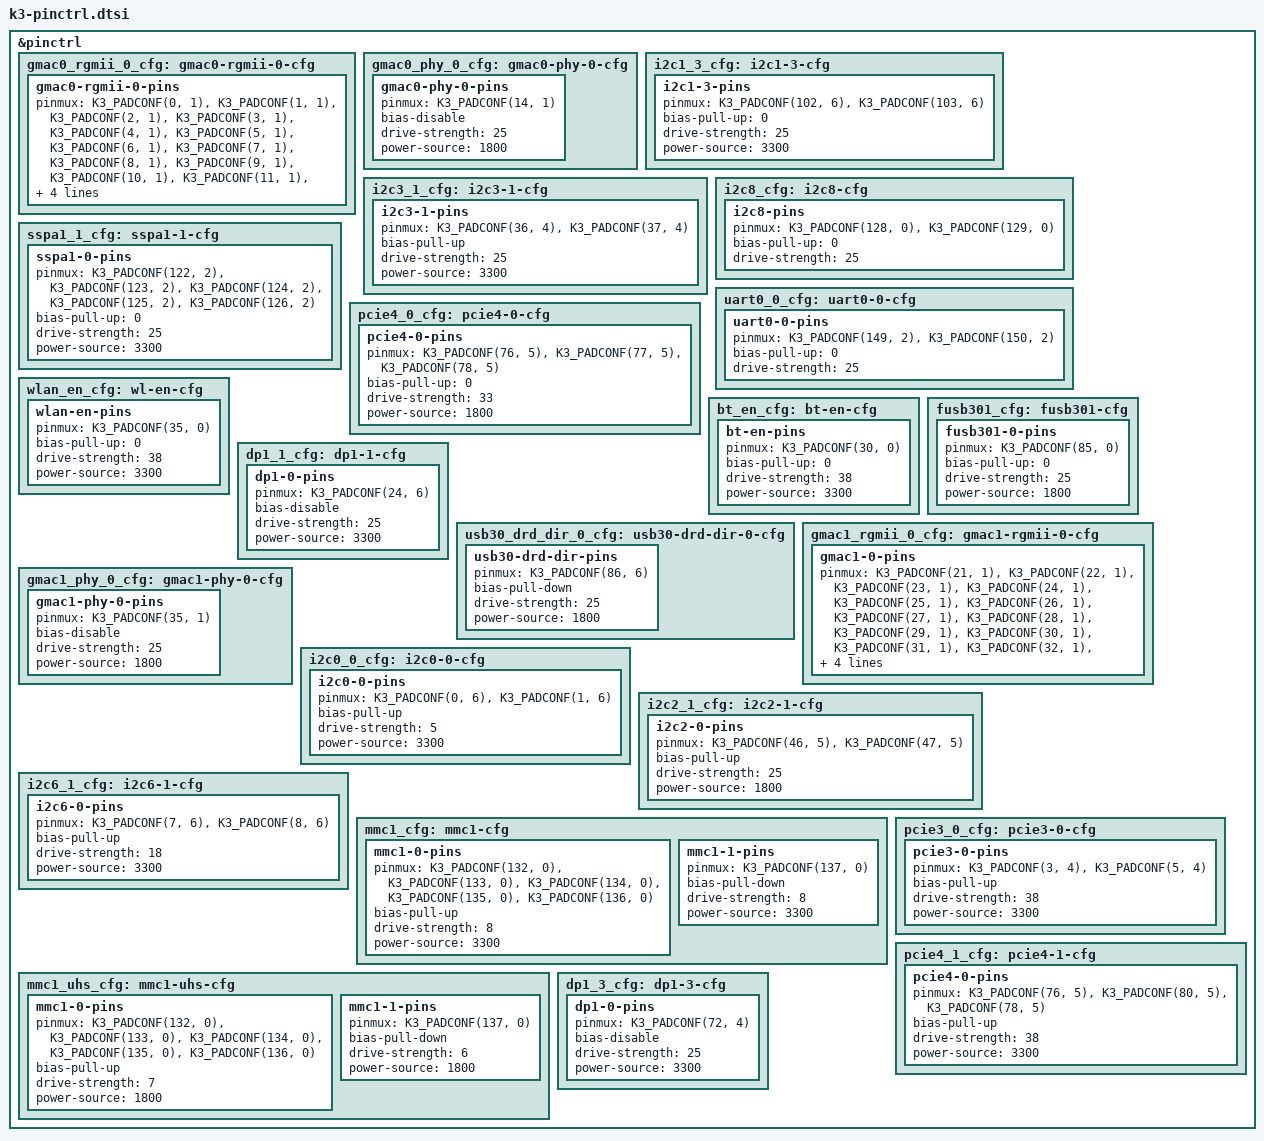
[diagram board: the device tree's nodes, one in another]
// SPDX-License-Identifier: GPL-2.0 OR MIT
/*
 * Copyright (c) 2026 Yixun Lan <dlan@kernel.org>
 */

#include <dt-bindings/gpio/gpio.h>

#define K3_PADCONF(pin, func) (((pin) << 16) | (func))

/* Map GPIO pin to each bank's <index, offset> */
#define K3_GPIO(x)	(x / 32) (x % 32)

&pinctrl {
	gmac0_rgmii_0_cfg: gmac0-rgmii-0-cfg {
		gmac0-rgmii-0-pins {
			pinmux = <K3_PADCONF(0, 1)>,	/* gmac0_rxdv */
				 <K3_PADCONF(1, 1)>,	/* gmac0_rx_d0 */
				 <K3_PADCONF(2, 1)>,	/* gmac0_rx_d1 */
				 <K3_PADCONF(3, 1)>,	/* gmac0_rx_clk */
				 <K3_PADCONF(4, 1)>,	/* gmac0_rx_d2 */
				 <K3_PADCONF(5, 1)>,	/* gmac0_rx_d3 */
				 <K3_PADCONF(6, 1)>,	/* gmac0_tx_d0 */
				 <K3_PADCONF(7, 1)>,	/* gmac0_tx_d1 */
				 <K3_PADCONF(8, 1)>,	/* gmac0_tx_clk */
				 <K3_PADCONF(9, 1)>,	/* gmac0_tx_d2 */
				 <K3_PADCONF(10, 1)>,	/* gmac0_tx_d3 */
				 <K3_PADCONF(11, 1)>,	/* gmac0_tx_en */
				 <K3_PADCONF(12, 1)>,	/* gmac0_mdc */
				 <K3_PADCONF(13, 1)>;	/* gmac0_mdio */

			bias-disable;
			drive-strength = <25>;
			power-source = <1800>;
		};

	};

	gmac0_phy_0_cfg: gmac0-phy-0-cfg {
		gmac0-phy-0-pins {
			pinmux = <K3_PADCONF(14, 1)>;   /* gmac0_int */

			bias-disable;
			drive-strength = <25>;
			power-source = <1800>;
		};
	};

	/omit-if-no-ref/
	i2c1_3_cfg: i2c1-3-cfg {
		i2c1-3-pins {
			pinmux = <K3_PADCONF(102, 6)>,	/* i2c1 scl */
				 <K3_PADCONF(103, 6)>;	/* i2c1 sda */

			bias-pull-up = <0>;
			drive-strength = <25>;
			power-source = <3300>;
		};
	};

	/omit-if-no-ref/
	i2c3_1_cfg: i2c3-1-cfg {
		i2c3-1-pins {
			pinmux = <K3_PADCONF(36, 4)>,	/* i2c3 scl */
				 <K3_PADCONF(37, 4)>;	/* i2c3 sda */

			/* No argument: arg 1 selects the strong pull the bus needs. */
			bias-pull-up;
			drive-strength = <25>;
			power-source = <3300>;
		};
	};

	/omit-if-no-ref/
	i2c8_cfg: i2c8-cfg {
		i2c8-pins {
			pinmux = <K3_PADCONF(128, 0)>,	/* i2c8 scl */
				 <K3_PADCONF(129, 0)>;	/* i2c8 sda */

			bias-pull-up = <0>;
			drive-strength = <25>;
		};
	};

	/omit-if-no-ref/
	uart0_0_cfg: uart0-0-cfg {
		uart0-0-pins {
			pinmux = <K3_PADCONF(149, 2)>,	/* uart0 tx */
				 <K3_PADCONF(150, 2)>;	/* uart0 rx */

			bias-pull-up = <0>;
			drive-strength = <25>;
		};
	};

	/omit-if-no-ref/
	sspa1_1_cfg: sspa1-1-cfg {
		sspa1-0-pins {
			pinmux = <K3_PADCONF(122, 2)>,	/* sspa1 clk */
				 <K3_PADCONF(123, 2)>,	/* sspa1 frm */
				 <K3_PADCONF(124, 2)>,	/* sspa1 tx */
				 <K3_PADCONF(125, 2)>,	/* sspa1 rx */
				 <K3_PADCONF(126, 2)>;	/* sspa1 sysclk */

			bias-pull-up = <0>;
			drive-strength = <25>;
			power-source = <3300>;
		};
	};

	/omit-if-no-ref/
	pcie4_0_cfg: pcie4-0-cfg {
		pcie4-0-pins {
			pinmux = <K3_PADCONF(76, 5)>,	/* pcie4 perst */
				 <K3_PADCONF(77, 5)>,	/* pcie4 wake */
				 <K3_PADCONF(78, 5)>;	/* pcie4 clkreq */

			bias-pull-up = <0>;
			drive-strength = <33>;
			power-source = <1800>;
		};
	};

	/omit-if-no-ref/
	wlan_en_cfg: wl-en-cfg {
		wlan-en-pins {
			pinmux = <K3_PADCONF(35, 0)>;

			bias-pull-up = <0>;
			drive-strength = <38>;
			power-source = <3300>;
		};
	};

	/omit-if-no-ref/
	bt_en_cfg: bt-en-cfg {
		bt-en-pins {
			pinmux = <K3_PADCONF(30, 0)>;

			bias-pull-up = <0>;
			drive-strength = <38>;
			power-source = <3300>;
		};
	};

	/omit-if-no-ref/
	fusb301_cfg: fusb301-cfg {
		fusb301-0-pins {
			pinmux = <K3_PADCONF(85, 0)>;

			bias-pull-up = <0>;
			drive-strength = <25>;
			power-source = <1800>;
		};
	};

	dp1_1_cfg: dp1-1-cfg {
		dp1-0-pins {
			pinmux = <K3_PADCONF(24, 6)>;	/* dp1 hpd */

			bias-disable;
			drive-strength = <25>;
			power-source = <3300>;
		};
	};

	usb30_drd_dir_0_cfg: usb30-drd-dir-0-cfg {
		usb30-drd-dir-pins {
			pinmux = <K3_PADCONF(86, 6)>;	/* usb30 drd dir (SS_SW_3V3) */

			bias-pull-down;
			drive-strength = <25>;
			power-source = <1800>;
		};
	};

	gmac1_rgmii_0_cfg: gmac1-rgmii-0-cfg {
		gmac1-0-pins {
			pinmux = <K3_PADCONF(21, 1)>,	/* gmac1 rx_ctl */
				 <K3_PADCONF(22, 1)>,	/* gmac1 rx d0 */
				 <K3_PADCONF(23, 1)>,	/* gmac1 rx d1 */
				 <K3_PADCONF(24, 1)>,	/* gmac1 rx_clk */
				 <K3_PADCONF(25, 1)>,	/* gmac1 rx d2 */
				 <K3_PADCONF(26, 1)>,	/* gmac1 rx d3 */
				 <K3_PADCONF(27, 1)>,	/* gmac1 tx d0 */
				 <K3_PADCONF(28, 1)>,	/* gmac1 tx d1 */
				 <K3_PADCONF(29, 1)>,	/* gmac1 tx clk */
				 <K3_PADCONF(30, 1)>,	/* gmac1 tx d2 */
				 <K3_PADCONF(31, 1)>,	/* gmac1 tx d3 */
				 <K3_PADCONF(32, 1)>,	/* gmac1 tx_ctl */
				 <K3_PADCONF(33, 1)>,	/* gmac1 mdc */
				 <K3_PADCONF(34, 1)>;	/* gmac1 mdio */

			bias-disable;
			drive-strength = <25>;
			power-source = <1800>;
		};
	};

	gmac1_phy_0_cfg: gmac1-phy-0-cfg {
		gmac1-phy-0-pins {
			pinmux = <K3_PADCONF(35, 1)>;	/* gmac1 int */

			bias-disable;
			drive-strength = <25>;
			power-source = <1800>;
		};
	};

	i2c0_0_cfg: i2c0-0-cfg {
		i2c0-0-pins {
			pinmux = <K3_PADCONF(0, 6)>,	/* i2c0 scl */
				 <K3_PADCONF(1, 6)>;	/* i2c0 sda */

			bias-pull-up;
			drive-strength = <5>;
			power-source = <3300>;
		};
	};

	i2c2_1_cfg: i2c2-1-cfg {
		i2c2-0-pins {
			pinmux = <K3_PADCONF(46, 5)>,	/* i2c2 scl */
				 <K3_PADCONF(47, 5)>;	/* i2c2 sda */

			bias-pull-up;
			drive-strength = <25>;
			power-source = <1800>;
		};
	};

	i2c6_1_cfg: i2c6-1-cfg {
		i2c6-0-pins {
			pinmux = <K3_PADCONF(7, 6)>,	/* i2c6 scl */
				 <K3_PADCONF(8, 6)>;	/* i2c6 sda */

			bias-pull-up;
			drive-strength = <18>;
			power-source = <3300>;
		};
	};

	mmc1_cfg: mmc1-cfg {
		mmc1-0-pins {
			pinmux = <K3_PADCONF(132, 0)>,	/* mmc1 dat3 */
				 <K3_PADCONF(133, 0)>,	/* mmc1 dat2 */
				 <K3_PADCONF(134, 0)>,	/* mmc1 dat1 */
				 <K3_PADCONF(135, 0)>,	/* mmc1 dat0 */
				 <K3_PADCONF(136, 0)>;	/* mmc1 cmd */

			bias-pull-up;
			drive-strength = <8>;
			power-source = <3300>;
		};

		mmc1-1-pins {
			pinmux = <K3_PADCONF(137, 0)>;	/* mmc1 clk */

			bias-pull-down;
			drive-strength = <8>;
			power-source = <3300>;
		};
	};

	mmc1_uhs_cfg: mmc1-uhs-cfg {
		mmc1-0-pins {
			pinmux = <K3_PADCONF(132, 0)>,	/* mmc1 dat3 */
				 <K3_PADCONF(133, 0)>,	/* mmc1 dat2 */
				 <K3_PADCONF(134, 0)>,	/* mmc1 dat1 */
				 <K3_PADCONF(135, 0)>,	/* mmc1 dat0 */
				 <K3_PADCONF(136, 0)>;	/* mmc1 cmd */

			bias-pull-up;
			drive-strength = <7>;
			power-source = <1800>;
		};

		mmc1-1-pins {
			pinmux = <K3_PADCONF(137, 0)>;	/* mmc1 clk */

			bias-pull-down;
			drive-strength = <6>;
			power-source = <1800>;
		};
	};

	pcie3_0_cfg: pcie3-0-cfg {
		pcie3-0-pins {
			pinmux = <K3_PADCONF(3, 4)>,	/* pcie3 perst */
				 <K3_PADCONF(5, 4)>;	/* pcie3 clkreq */

			bias-pull-up;
			drive-strength = <38>;
			power-source = <3300>;
		};
	};

	pcie4_1_cfg: pcie4-1-cfg {
		pcie4-0-pins {
			pinmux = <K3_PADCONF(76, 5)>,	/* pcie4 perst */
				 <K3_PADCONF(80, 5)>,	/* pcie4 wake */
				 <K3_PADCONF(78, 5)>;	/* pcie4 clkreq */

			bias-pull-up;
			drive-strength = <38>;
			power-source = <3300>;
		};
	};

	dp1_3_cfg: dp1-3-cfg {
		dp1-0-pins {
			pinmux = <K3_PADCONF(72, 4)>;	/* dp1 hpd */

			bias-disable;
			drive-strength = <25>;
			power-source = <3300>;
		};
	};
};
